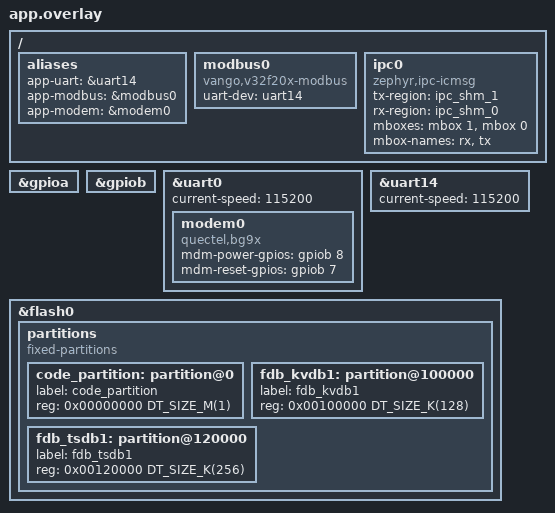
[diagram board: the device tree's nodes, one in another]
&gpioa { status = "okay"; };
&gpiob { status = "okay"; };

&uart0 {
    status = "okay";
    current-speed = <115200>;
    
    modem0: modem0 {
        compatible = "quectel,bg9x";
        mdm-power-gpios = <&gpiob 8 GPIO_ACTIVE_HIGH>;
        mdm-reset-gpios = <&gpiob 7 GPIO_ACTIVE_HIGH>;
        status = "okay";
    };
};

&uart14 {
    status = "okay";
    current-speed = <115200>;
};

&flash0 {
        partitions {
                compatible = "fixed-partitions";
                #address-cells = <1>;
                #size-cells = <1>;

                code_partition: partition@0 {
                        label = "code_partition";
                        reg = <0x00000000 DT_SIZE_M(1)>;
                };

                fdb_kvdb1: partition@100000 {
                        label = "fdb_kvdb1";
                        reg = <0x00100000 DT_SIZE_K(128)>;
                };

                fdb_tsdb1: partition@120000 {
                        label = "fdb_tsdb1";
                        reg = <0x00120000 DT_SIZE_K(256)>;
                };
        };
};

/ {
    aliases {
        app-uart = &uart14;
        app-modbus = &modbus0;
        app-modem = &modem0;
    };

    modbus0: modbus0 {
        compatible = "vango,v32f20x-modbus";
        status = "okay";
        uart-dev = <&uart14>;
    };

    ipc0: ipc0 {
        compatible = "zephyr,ipc-icmsg";
        tx-region = <&ipc_shm_1>;
        rx-region = <&ipc_shm_0>;
        mboxes = <&mbox 1>, <&mbox 0>;
        mbox-names = "rx", "tx";
        status = "okay";
    };
};
